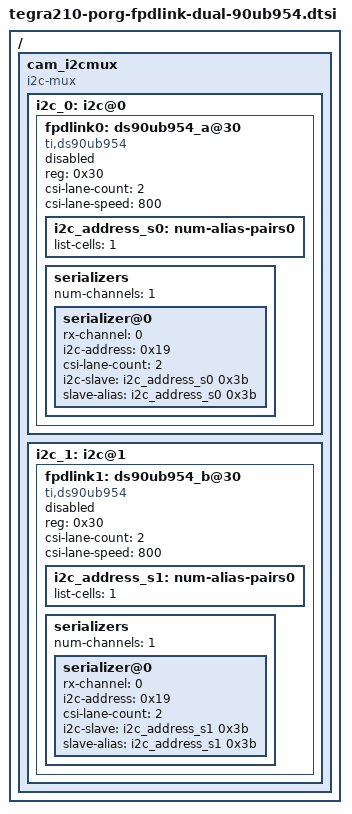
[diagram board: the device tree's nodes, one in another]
/*
 * Copyright (c) 2018-2019, NVIDIA CORPORATION.  All rights reserved.
 *
 * This program is free software; you can redistribute it and/or modify
 * it under the terms of the GNU General Public License as published by
 * the Free Software Foundation; either version 2 of the License, or
 * (at your option) any later version.
 *
 * This program is distributed in the hope that it will be useful, but WITHOUT
 * ANY WARRANTY; without even the implied warranty of MERCHANTABILITY or
 * FITNESS FOR A PARTICULAR PURPOSE.  See the GNU General Public License for
 * more details.
 *
 * You should have received a copy of the GNU General Public License
 * along with this program.  If not, see <http://www.gnu.org/licenses/>.
 */

/ {
	cam_i2cmux {
	i2c_0: i2c@0 {
            fpdlink0: ds90ub954_a@30 {
            compatible = "ti,ds90ub954";
            reg = <0x30>;
            status = "disabled";
            csi-lane-count = <2>;
            csi-lane-speed = <800>;
            //continuous-clock;
            //pdb-gpio = <&gpio TEGRA_GPIO(S, 7) 0>;
            //pass-gpio = <&gpio TEGRA_GPIO(S, 0) 0>;
            //lock-gpio = <&gpio TEGRA_GPIO(T, 0) 0>;
            i2c_address_s0: num-alias-pairs0 {list-cells = <1>;};
            serializers {
                status = "okay";
                num-channels = <1>;
                #address-cells = <1>;
                #size-cells = <0>;
                serializer@0 {
                    status = "okay";
                    rx-channel=<0>;
                    i2c-address=<0x19>;
                    csi-lane-count = <2>;
                    i2c-slave = <&i2c_address_s0 0x3b>;
                    slave-alias = <&i2c_address_s0 0x3b>;
                };
            };
        };
    };
    i2c_1: i2c@1 {
            fpdlink1: ds90ub954_b@30 {
            compatible = "ti,ds90ub954";
            reg = <0x30>;
            status = "disabled";
            csi-lane-count = <2>;
            csi-lane-speed = <800>;
            //continuous-clock;
            //pdb-gpio = <&gpio TEGRA_GPIO(S, 7) 0>;
            //pass-gpio = <&gpio TEGRA_GPIO(S, 0) 0>;
            //lock-gpio = <&gpio TEGRA_GPIO(T, 0) 0>;
            i2c_address_s1: num-alias-pairs0 {list-cells = <1>;};
            serializers {
                status = "okay";
                num-channels = <1>;
                #address-cells = <1>;
                #size-cells = <0>;
                serializer@0 {
                    status = "okay";
                    rx-channel=<0>;
                    i2c-address=<0x19>;
                    csi-lane-count = <2>;
                    i2c-slave = <&i2c_address_s1 0x3b>;
                    slave-alias = <&i2c_address_s1 0x3b>;
                };
            };
        };
    };
};
};
